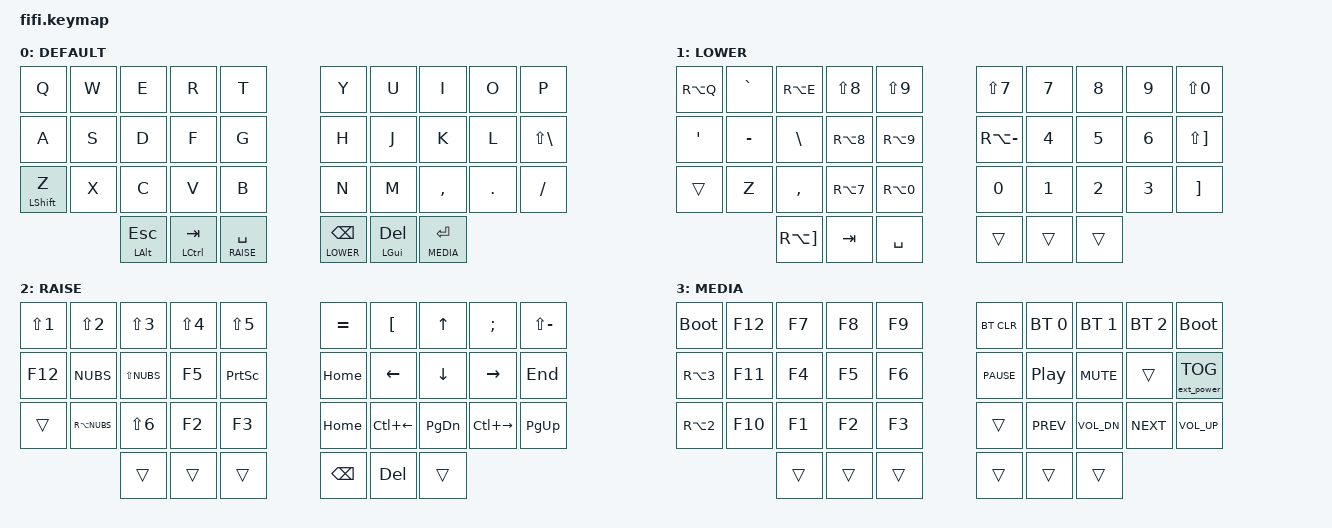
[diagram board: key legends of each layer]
#include <behaviors.dtsi>
#include <dt-bindings/zmk/bt.h>
#include <dt-bindings/zmk/keys.h>
#include <dt-bindings/zmk/matrix_transform.h>
#include <dt-bindings/zmk/outputs.h>
#include <dt-bindings/zmk/ext_power.h>

#define DEFAULT 0
#define LOWER 1
#define RAISE 2
#define MEDIA 3

/ {
  behaviors {
    hm: homerow_mods {
        compatible = "zmk,behavior-hold-tap";
        label = "HOMEROW_MODS";
        #binding-cells = <2>;
        tapping-term-ms = <120>;
        quick_tap_ms = <0>;
        flavor = "tap-preferred";
        bindings = <&kp>, <&kp>;
    };
    lm: layer_mod_tap {
        compatible = "zmk,behavior-hold-tap";
        label = "layer_hold_tap";
        #binding-cells = <2>;
        tapping-term-ms = <120>;
        quick-tap-ms = <0>;
        flavor = "tap-preferred";
        bindings = <&mo>, <&kp>;
    };
  };

  keymap {
    compatible = "zmk,keymap";

// In default_layer vorh:	, ;		. :		- _		' #		+ *		(DETUSCHE BELEGUNG BEI NUTZUNG VON SHIFT)
// Gegensätzlich, einzeln: ( )		{ }		[ ]		< > 	/ \		& |
// Gegensätzlich, shift: 	´ `		^ °
// Einzeln: 				!	"	§	$	% 	= 	? 	@	€	~	²	³
// Hilfreiches: 			Del		Bild_up Bild_dn	Pos1 	Ende 	Druck
// F-Tasten: 				F1		F2		...		F12
// STRG-Tastenkombis: 		cpy C	pst V	cut X 	undo Z	find F 	repl H
// Medien-Tasten:			mt_spk	mt_mic	vol_dwn	vol_up	play	pause	prev	next
// Ignorieren:				Einfg	NUM		Rollen	Pause

// Thumb keys: ESC/ALT, TAB/CTRL, SPACE/RAISE - BSP/LOWER, DEL/GUI, RET/MEDIA

// Optimized for German Layout
// Shift key only on the left side. Shared with y key.
// qwert zuiop
// asdfg hjkl'
// Sxcvb nm,.-
//   ETS BDE
    default_layer {
        label = "DEFAULT";
        bindings = <
&kp Q           &kp W       &kp E       &kp R       &kp T                   &kp Y           &kp U       &kp I       &kp O       &kp P
&kp A           &kp S       &kp D       &kp F       &kp G                   &kp H           &kp J       &kp K		    &kp L       &kp LS(BSLH)
&hm LSHIFT Z    &kp X       &kp C       &kp V       &kp B                   &kp N           &kp M       &kp COMMA   &kp DOT     &kp FSLH
                    &hm LALT ESC   &hm LCTRL TAB    &lm RAISE SPACE         &lm LOWER BSPC   &hm LGUI DEL   &lm MEDIA RET
        >;
    };

// Optimized for German Layout
// @^€() /789=
// äß#[] \456*
// SY,{} 0123+
//   ~TS BDE
    lower_layer {
        label = "LOWER";
        bindings = <
&kp RA(Q)	  &kp GRAVE   &kp RA(E)       &kp LS(N8)	&kp LS(N9)			    &kp LS(N7)	    &kp N7		&kp N8		&kp N9      &kp LS(N0)
&kp QUOT	  &kp MINUS   &kp BSLH	      &kp RA(N8)	&kp RA(N9)			    &kp RA(MINUS)	  &kp N4    &kp N5		&kp N6	    &kp LS(RBKT)
&trans      &kp Z       &kp COMMA       &kp RA(N7)	&kp RA(N0)			    &kp N0		      &kp N1    &kp N2		&kp N3	    &kp RBKT
                        &kp RA(RBKT)    &kp TAB     &kp SPACE           &trans          &trans    &trans
        >;
    };

// Optimized for German Layout
// !"§$% ´üUö?
// 2<>5P HLDRE
// S|&23 HLBRB
//   ETS BDE
    raise_layer {
        label = "RAISE";
        bindings = <
&kp LS(N1)  &kp LS(N2)  &kp LS(N3)      &kp LS(N4)  &kp LS(N5)              &kp EQUAL       &kp LBKT    &kp UP      &kp SEMI     &kp LS(MINUS)
&kp F12     &kp NUBS    &kp LS(NUBS)    &kp F5      &kp PSCRN               &kp HOME        &kp LEFT    &kp DOWN    &kp RIGHT    &kp END
&trans      &kp RA(NUBS)&kp LS(N6)      &kp F2      &kp F3                  &kp HOME        &kp LC(LEFT)&kp PG_DN   &kp LC(RIGHT)&kp PG_UP
                        &trans          &trans      &trans                  &kp BSPC        &kp DEL     &trans
                                                
        >;
    };


    media_layer {
        label = "MEDIA";
        bindings = <
&bootloader &kp F12     &kp F7          &kp F8      &kp F9                  &bt BT_CLR      &bt BT_SEL 0&bt BT_SEL 1&bt BT_SEL 2&bootloader
&kp RA(N3)  &kp F11     &kp F4          &kp F5      &kp F6                  &kp C_PAUSE     &kp C_PP    &kp C_MUTE  &trans      &ext_power EP_TOG
&kp RA(N2)  &kp F10     &kp F1          &kp F2      &kp F3                  &trans          &kp C_PREV  &kp C_VOL_DN&kp C_NEXT  &kp C_VOL_UP
                        &trans          &trans      &trans                  &trans          &trans      &trans
        >;
    };
  };
};
